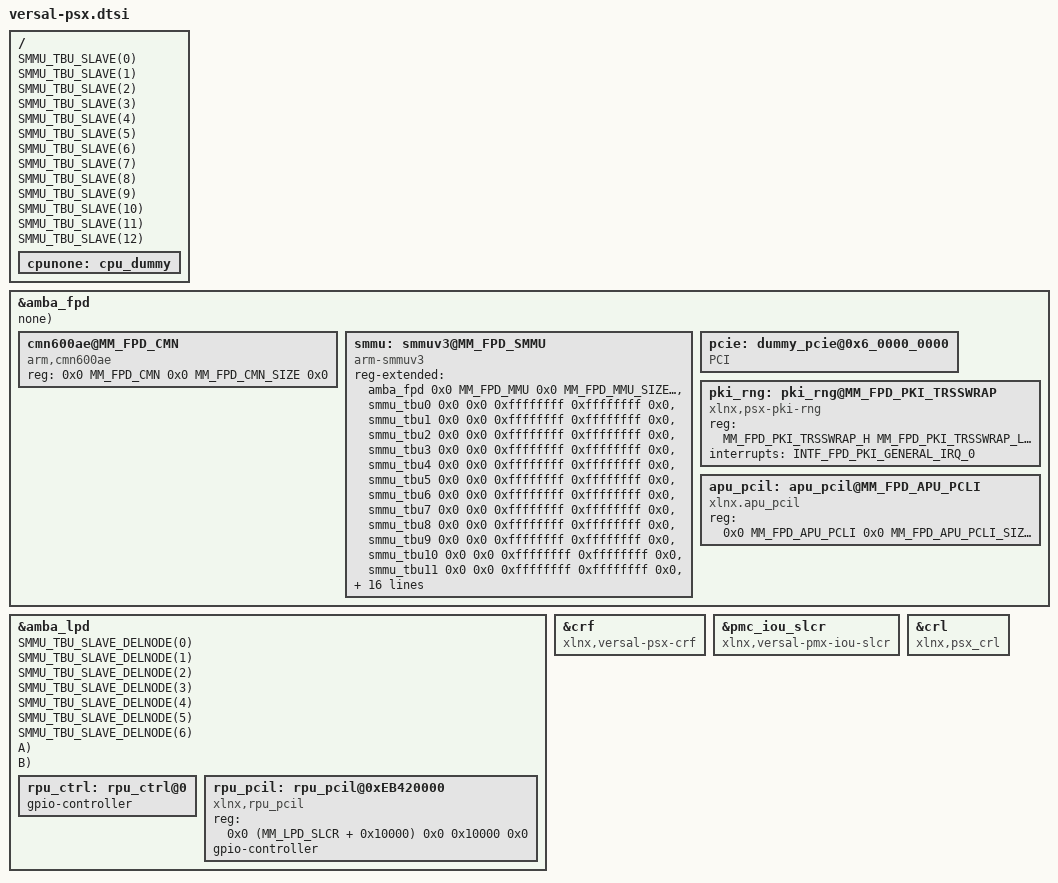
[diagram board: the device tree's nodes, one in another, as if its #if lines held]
/*
 * Versal PSX Overlay
 *
 * Copyright (C) 2021-2022 Xilinx Inc.
 * Copyright (C) 2022-2023 Advanced Micro Devices Inc.
 * All rights Reserved.
 *
 * Redistribution and use in source and binary forms, with or without
 * modification, are permitted provided that the following conditions are met:
 *     * Redistributions of source code must retain the above copyright
 *       notice, this list of conditions and the following disclaimer.
 *     * Redistributions in binary form must reproduce the above copyright
 *       notice, this list of conditions and the following disclaimer in the
 *       documentation and/or other materials provided with the distribution.
 *     * Neither the name of the <organization> nor the
 *       names of its contributors may be used to endorse or promote products
 *       derived from this software without specific prior written permission.
 *
 * THIS SOFTWARE IS PROVIDED BY THE COPYRIGHT HOLDERS AND CONTRIBUTORS "AS IS" AND
 * ANY EXPRESS OR IMPLIED WARRANTIES, INCLUDING, BUT NOT LIMITED TO, THE IMPLIED
 * WARRANTIES OF MERCHANTABILITY AND FITNESS FOR A PARTICULAR PURPOSE ARE
 * DISCLAIMED. IN NO EVENT SHALL <COPYRIGHT HOLDER> BE LIABLE FOR ANY
 * DIRECT, INDIRECT, INCIDENTAL, SPECIAL, EXEMPLARY, OR CONSEQUENTIAL DAMAGES
 * (INCLUDING, BUT NOT LIMITED TO, PROCUREMENT OF SUBSTITUTE GOODS OR SERVICES;
 * LOSS OF USE, DATA, OR PROFITS; OR BUSINESS INTERRUPTION) HOWEVER CAUSED AND
 * ON ANY THEORY OF LIABILITY, WHETHER IN CONTRACT, STRICT LIABILITY, OR TORT
 * (INCLUDING NEGLIGENCE OR OTHERWISE) ARISING IN ANY WAY OUT OF THE USE OF THIS
 * SOFTWARE, EVEN IF ADVISED OF THE POSSIBILITY OF SUCH DAMAGE.
 */

#include "versal.dtsh"
#include "smmuv2.dtsh"

#define MM_FPD_CMN			0xa0000000
#define MM_FPD_CMN_SIZE			0x03000000

#define CRL_RST_RPU_A_0 35
#define CRL_RST_RPU_A_1 36
#define CRL_RST_RPU_B_0 37
#define CRL_RST_RPU_B_1 38

#define GEN_APU_CLUSTER(n, a, b, c, d)					\
	apu_cluster ## n: apu_cluster@MM_FPD_FPD_APU_CLUSTER ## n {	\
		#gpio-cells = <1>;					\
		gpio-controller;					\
		compatible = "xlnx,versal-apu-ctrl";			\
		reg = <0x0 MM_FPD_APU_CLUSTER ## n			\
		       0x0 MM_FPD_APU_CLUSTER0_SIZE 0x0>;		\
		cpu0 = <&cpu ## a>;					\
		cpu1 = <&cpu ## b>;					\
		cpu2 = <&cpu ## c>;					\
		cpu3 = <&cpu ## d>;					\
		cores-per-cluster = <NUM_APUS_PER_CLUSTER>;		\
	}

/* Dummy node.  */
/ { cpunone: cpu_dummy { }; };

#if NUM_APUS_PER_CLUSTER == 2
&amba_fpd {
	GEN_APU_CLUSTER(0, 0, 1, none, none);
	GEN_APU_CLUSTER(1, 2, 3, none, none);
	GEN_APU_CLUSTER(2, 4, 5, none, none);
	GEN_APU_CLUSTER(3, 6, 7, none, none);
};
#else
&amba_fpd {
	GEN_APU_CLUSTER(0, 0, 1, 2, 3);
	GEN_APU_CLUSTER(1, 4, 5, 6, 7);
	GEN_APU_CLUSTER(2, 8, 9, 10, 11);
	GEN_APU_CLUSTER(3, 12, 13, 14, 15);
};

#endif

&amba_lpd {
	/* Remove Versal SMMUv2 defintions */
	SMMU_TBU_SLAVE_DELNODE(0);
	SMMU_TBU_SLAVE_DELNODE(1);
	SMMU_TBU_SLAVE_DELNODE(2);
	SMMU_TBU_SLAVE_DELNODE(3);
	SMMU_TBU_SLAVE_DELNODE(4);
	SMMU_TBU_SLAVE_DELNODE(5);
	SMMU_TBU_SLAVE_DELNODE(6);
	/delete-node/ smmu@MM_FPD_FPD_SMMUTCU;
	/delete-node/ smmu0@MM_FPD_FPD_SMMU;
};

/* SMMU TBUs. See PSX FPD spec. */
/ {
	SMMU_TBU_SLAVE(0);
	SMMU_TBU_SLAVE(1);
	SMMU_TBU_SLAVE(2);
	SMMU_TBU_SLAVE(3);
	SMMU_TBU_SLAVE(4);
	SMMU_TBU_SLAVE(5);
	SMMU_TBU_SLAVE(6);
	SMMU_TBU_SLAVE(7);
	SMMU_TBU_SLAVE(8);
	SMMU_TBU_SLAVE(9);
	SMMU_TBU_SLAVE(10);
	SMMU_TBU_SLAVE(11);
	SMMU_TBU_SLAVE(12);
};

&amba_fpd {
	/*
	 * Versal Net PSX replaces the CCI-500 with a CMN-600AE.
	 * Delete the old nodes and add the CMN.
	 */
	/delete-node/ cci_reg@MM_FPD_FPD_GPCCI;
	/delete-node/ cci500@MM_FPD_FPD_MAINCCI;
	cmn600ae@MM_FPD_CMN {
		compatible = "arm,cmn600ae";
		reg = <0x0 MM_FPD_CMN 0x0 MM_FPD_CMN_SIZE 0x0>;
	};

	smmu: smmuv3@MM_FPD_SMMU {
		compatible = "arm-smmuv3";
		reg-extended = <&amba_fpd 0x0 MM_FPD_MMU 0x0 MM_FPD_MMU_SIZE 0x0
					    &smmu_tbu0 0x0 0x0 0xffffffff 0xffffffff 0x0
					    &smmu_tbu1 0x0 0x0 0xffffffff 0xffffffff 0x0
					    &smmu_tbu2 0x0 0x0 0xffffffff 0xffffffff 0x0
					    &smmu_tbu3 0x0 0x0 0xffffffff 0xffffffff 0x0
					    &smmu_tbu4 0x0 0x0 0xffffffff 0xffffffff 0x0
					    &smmu_tbu5 0x0 0x0 0xffffffff 0xffffffff 0x0
					    &smmu_tbu6 0x0 0x0 0xffffffff 0xffffffff 0x0
					    &smmu_tbu7 0x0 0x0 0xffffffff 0xffffffff 0x0
					    &smmu_tbu8 0x0 0x0 0xffffffff 0xffffffff 0x0
					    &smmu_tbu9 0x0 0x0 0xffffffff 0xffffffff 0x0
					    &smmu_tbu10 0x0 0x0 0xffffffff 0xffffffff 0x0
					    &smmu_tbu11 0x0 0x0 0xffffffff 0xffffffff 0x0
					    &smmu_tbu12 0x0 0x0 0xffffffff 0xffffffff 0x0
					    >;

		mr-0 = <&amba>;
		mr-1 = <&amba>;
		mr-2 = <&amba>;
		mr-3 = <&amba>;
		mr-4 = <&amba>;
		mr-5 = <&amba>;
		mr-6 = <&amba>;
		mr-7 = <&amba>;
		mr-8 = <&amba>;
		mr-9 = <&amba>;
		mr-10 = <&amba>;
		mr-11 = <&amba>;
		mr-12 = <&amba>;

		dma_mr = <&amba>;
		primary-bus = <&pcie>;
	};

	/* Dummy PCIe device so SMMUv3 model is happy */
	pcie: dummy_pcie@0x6_0000_0000 {
		compatible = "PCI";
	};

	/* PKI */
	pki_rng: pki_rng@MM_FPD_PKI_TRSSWRAP {
		compatible = "xlnx,psx-pki-rng";
		reg = <MM_FPD_PKI_TRSSWRAP_H MM_FPD_PKI_TRSSWRAP_L
			0x0
			(MM_FPD_PKI_TRSSWRAP_SIZE + MM_FPD_PKI_CTRLSTAT_SIZE)
			0x0>;
		interrupts = <INTF_FPD_PKI_GENERAL_IRQ_0>;
	};

	apu_pcil: apu_pcil@MM_FPD_APU_PCLI {
		compatible = "xlnx.apu_pcil";
		reg = <0x0 MM_FPD_APU_PCLI 0x0 MM_FPD_APU_PCLI_SIZE 0x0>;
	};
};

&crf {
	compatible = "xlnx,versal-psx-crf";
};

&pmc_iou_slcr {
	compatible = "xlnx,versal-pmx-iou-slcr";
};

&crl {
	compatible = "xlnx,psx_crl";
};

#define GEN_RPU_CTRL(clow, cup)										      \
	rpu_ctrl_ ## clow: rpu_cluster@MM_PSX_RPU_CLUSTER_ ## cup {					      \
		compatible = "xlnx,psx_rpu_cluster_2.0";						      \
		reg = <0x0 MM_PSX_RPU_CLUSTER_ ## cup 0x0 MM_PSX_RPU_CLUSTER_ ## cup ## _SIZE 0x0>;	      \
		#gpio-cells = <1>;									      \
		gpio-controller;									      \
	};												      \
	rpu_ctrl_ ## clow ## 0: rpu_ctrl_ ## clow ## 0@MM_PSX_RPU_CLUSTER_ ## cup ## 0 {		      \
		compatible = "xlnx,psx_rpu_cluster_core0";						      \
		reg = <0x0 MM_PSX_RPU_CLUSTER_ ## cup ## 0 0x0 MM_PSX_RPU_CLUSTER_ ## cup ## 0 ## _SIZE 0x0>; \
		#gpio-cells = <1>;									      \
		gpio-controller;									      \
		gpios = <&crl CRL_RST_RPU_ ## cup ## _0>;						      \
	};												      \
	rpu_ctrl_ ## clow ## 1: rpu_ctrl_ ## clow ## 1@MM_PSX_RPU_CLUSTER_ ## cup ## 1 {		      \
		compatible = "xlnx,psx_rpu_cluster_core1";						      \
		reg = <0x0 MM_PSX_RPU_CLUSTER_ ## cup ## 1 0x0 MM_PSX_RPU_CLUSTER_ ## cup ## 1 ## _SIZE 0x0>; \
		#gpio-cells = <1>;									      \
		gpio-controller;									      \
		gpios = <&crl CRL_RST_RPU_ ## cup ## _1							      \
			&rpu_ctrl_ ## clow 0>;								      \
	}

&amba_lpd {
	rpu_ctrl: rpu_ctrl@0 {
		/*TODO: Delete this node after we connect
		 all the power management signal to psx-crl.
		*/
		#gpio-cells = <1>;
		gpio-controller;
	};

	GEN_RPU_CTRL(a, A);
	GEN_RPU_CTRL(b, B);

	rpu_pcil: rpu_pcil@0xEB420000 {
		compatible = "xlnx,rpu_pcil";
		reg = <0x0 (MM_LPD_SLCR + 0x10000) 0x0 0x10000 0x0>;
		gpio-controller;
		#gpio-cells = <1>;
	};
};
